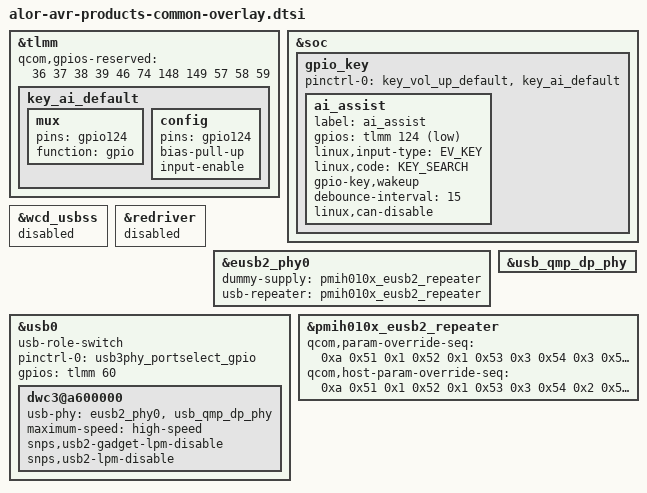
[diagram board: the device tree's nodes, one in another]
/* Copyright (c) 2025 Motorola Mobility LLC. All rights reserved.
 *
 * This program is free software; you can redistribute it and/or modify
 * it under the terms of the GNU General Public License version 2 and
 * only version 2 as published by the Free Software Foundation.
 *
 * This program is distributed in the hope that it will be useful,
 * but WITHOUT ANY WARRANTY; without even the implied warranty of
 * MERCHANTABILITY or FITNESS FOR A PARTICULAR PURPOSE.  See the
 * GNU General Public License for more details.
 */

/*
   This file is used for all avr products include prc, row, na etc.
*/

#include "alor-moto-common-overlay-base.dtsi"
#include "alor-moto-common-overlay.dtsi"
#include "moto-alor-avr-pmic.dtsi"
#include "alor-avr-touchscreen-thp-overlay.dtsi"

&tlmm {

        qcom,gpios-reserved = <36 37 38 39 46 74 148 149 57 58 59>;

	key_ai_default: key_ai_default {
		mux {
			pins = "gpio124";
			function = "gpio";
		};

		config {
			pins = "gpio124";
			bias-pull-up;
			input-enable;
		};
	};
};

&soc {
	gpio_key {
		pinctrl-names = "default";
		pinctrl-0 = <&key_vol_up_default>, <&key_ai_default>;

		ai_assist {
			label = "ai_assist";
			gpios = <&tlmm 124 GPIO_ACTIVE_LOW>;
			linux,input-type = <EV_KEY>;
			linux,code = <KEY_SEARCH>;
			gpio-key,wakeup;
			debounce-interval = <15>;
			linux,can-disable;
		};
	};
};

&wcd_usbss {
	status = "disabled";
};
&redriver {
	status = "disabled";
};

&eusb2_phy0 {
	dummy-supply = <&pmih010x_eusb2_repeater>;
	usb-repeater = <&pmih010x_eusb2_repeater>;
};

&usb_qmp_dp_phy {
	pinctrl-names = "unused";
};

&usb0 {
	usb-role-switch;
	pinctrl-names = "default";
	pinctrl-0 = <&usb3phy_portselect_gpio>;
	gpios = <&tlmm 60 0>;

	/delete-property/ ssusb_redriver;

	/delete-property/ qcom,wcd_usbss;

	dwc3@a600000 {
		usb-phy = <&eusb2_phy0>, <&usb_qmp_dp_phy>;
		maximum-speed = "high-speed";
		snps,usb2-gadget-lpm-disable;
		snps,usb2-lpm-disable;
	};
};

&pmih010x_eusb2_repeater {
	qcom,param-override-seq =
		/* <value reg_offset> */
		/* Adjust HS trasmit amplitude */
		<0xa 0x51
		/* HS termination resistor */
		 0x1 0x52
		/* HS disconnect threshold */
		 0x1 0x53
		/* Squelch detection threshold */
		 0x3 0x54
		/* USB2 Tx slew rate */
		 0x3 0x55
		/* USB2 Rx Equalization */
		 0x0 0x56
		/* Tx pre-emphasis tuning */
		 0x3 0x57>;
	qcom,host-param-override-seq =
		/* <value reg_offset> */
		/* Adjust HS trasmit amplitude */
		<0xa 0x51
		/* HS termination resistor */
		 0x1 0x52
		/* HS disconnect threshold */
		 0x1 0x53
		/* Squelch detection threshold */
		 0x3 0x54
		/* USB2 Tx slew rate */
		 0x2 0x55
		/* USB2 Rx Equalization */
		 0x0 0x56
		/* Tx pre-emphasis tuning */
		 0x3 0x57>;
};
